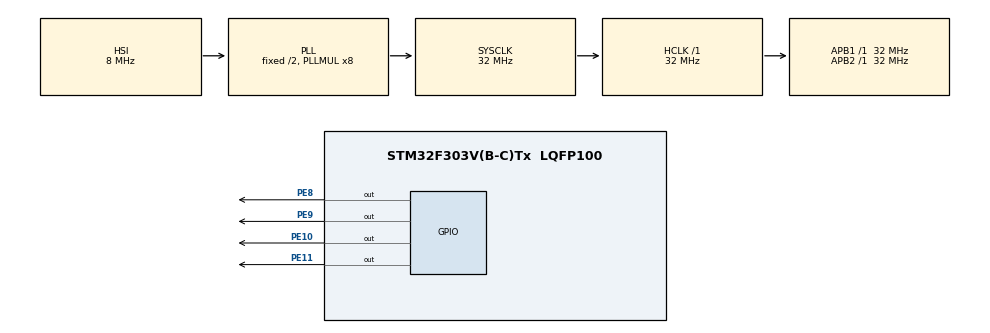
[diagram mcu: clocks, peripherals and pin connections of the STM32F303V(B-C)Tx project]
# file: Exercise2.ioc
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FREERTOS.Tasks01=defTask,24,128,StartDefaultTask,Default,NULL,Dynamic,NULL,NULL;BlinkLED,8,128,blink_LED,Default,NULL,Dynamic,NULL,NULL
FREERTOS.configUSE_IDLE_HOOK=1
Mcu.Family=STM32F3
Mcu.Name=STM32F303V(B-C)Tx
Mcu.Package=LQFP100
NVIC.PriorityGroup=NVIC_PRIORITYGROUP_4
NVIC.TIM1_UP_TIM16_IRQn=true\:0\:0\:false\:false\:true\:false\:false\:true
NVIC.TimeBase=TIM1_UP_TIM16_IRQn
NVIC.TimeBaseIP=TIM1
PE10.Signal=GPIO_Output
PE11.Signal=GPIO_Output
PE8.Signal=GPIO_Output
PE9.Signal=GPIO_Output
ProjectManager.HeapSize=0x200
ProjectManager.StackSize=0x400
ProjectManager.TargetToolchain=MDK-ARM V5.27
RCC.AHBFreq_Value=32000000
RCC.APB1Freq_Value=32000000
RCC.APB1TimFreq_Value=32000000
RCC.APB2Freq_Value=32000000
RCC.APB2TimFreq_Value=32000000
RCC.CortexFreq_Value=32000000
RCC.HCLKFreq_Value=32000000
RCC.HSE_VALUE=8000000
RCC.HSI_VALUE=8000000
RCC.LSE_VALUE=32768
RCC.PLLMUL=RCC_PLL_MUL8
RCC.SYSCLKFreq_VALUE=32000000
RCC.SYSCLKSourceVirtual=RCC_SYSCLKSOURCE_PLLCLK
RCC.USBFreq_Value=32000000
VP_FREERTOS_VS_CMSIS_V2.Mode=CMSIS_V2
VP_SYS_VS_tim1.Mode=TIM1
board=custom

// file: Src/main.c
/* USER CODE BEGIN Header */
/**
******************************************************************************
* @file           : main.c
* @brief          : Main program body
******************************************************************************
* @attention
*
* <h2><center>&copy; Copyright (c) 2020 STMicroelectronics.
* All rights reserved.</center></h2>
*
* This software component is licensed by ST under Ultimate Liberty license
* SLA0044, the "License"; You may not use this file except in compliance with
* the License. You may obtain a copy of the License at:
*                             www.st.com/SLA0044
*
******************************************************************************
*/
/* USER CODE END Header */

#include "main.h"
#include "cmsis_os.h"

#define CYCLE 6

/* Definitions for defTask */
osThreadId_t defTaskHandle;
const osThreadAttr_t defTask_attributes = {
	.name = "defTask",
	.priority = (osPriority_t) osPriorityNormal,
	.stack_size = 128
};
/* Definitions for BlinkLED */
osThreadId_t BlinkLEDHandle;
const osThreadAttr_t BlinkLED_attributes = {
	.name = "BlinkLED",
	.priority = (osPriority_t) osPriorityLow,
	.stack_size = 128
};

void SystemClock_Config(void);
static void MX_GPIO_Init(void);
void StartDefaultTask(void *argument);
void blink_LED(void *argument);

/* USER CODE BEGIN PFP */
osThreadId_t redBlinkTaskH;
osThreadId_t greenBlinkTaskH;
/* USER CODE END PFP */

int main(void)
{

	/* MCU Configuration--------------------------------------------------------*/

	/* Reset of all peripherals, Initializes the Flash interface and the Systick. */
	HAL_Init();

	/* Configure the system clock */
	SystemClock_Config();

	/* Initialize all configured peripherals */
	MX_GPIO_Init();
	/* Init scheduler */
	osKernelInitialize();

	/* Create the thread(s) */
	/* creation of defTask */
	defTaskHandle = osThreadNew(StartDefaultTask, NULL, &defTask_attributes);

	/* creation of BlinkLED */
	BlinkLEDHandle = osThreadNew(blink_LED, NULL, &BlinkLED_attributes);

	/* USER CODE BEGIN RTOS_THREADS */
	/* add threads, ... */

        /*
        * @brief Thread attribute to toggle red LED on GPIO9 on STM32 disccovery
        */
	const osThreadAttr_t redLed_attr = {
		.name = "Red",
		.priority = (osPriority_t) osPriorityLow,
		.stack_size = 128
	};
	redBlinkTaskH = osThreadNew(blink_LED, (uint16_t*)GPIO_PIN_9, &redLed_attr);

        /*
        * @brief Thread attribute to toggle green LED on GPIO11 on STM32
        */
	const osThreadAttr_t greenLed_attr = {
		.name = "Green",
		.priority = (osPriority_t) osPriorityLow,
		.stack_size = 128
	};
	greenBlinkTaskH = osThreadNew(blink_LED, (uint16_t*)GPIO_PIN_11, &greenLed_attr);

	/* USER CODE END RTOS_THREADS */

	/* Start scheduler */
	osKernelStart();

	/* We should never get here as control is now taken by the scheduler */

	/* Infinite loop */
	while (1)
	{

	}
}

void SystemClock_Config(void)
{
	RCC_OscInitTypeDef RCC_OscInitStruct = {0};
	RCC_ClkInitTypeDef RCC_ClkInitStruct = {0};

	/** Initializes the CPU, AHB and APB busses clocks
	 */
	RCC_OscInitStruct.OscillatorType = RCC_OSCILLATORTYPE_HSI;
	RCC_OscInitStruct.HSIState = RCC_HSI_ON;
	RCC_OscInitStruct.HSICalibrationValue = RCC_HSICALIBRATION_DEFAULT;
	RCC_OscInitStruct.PLL.PLLState = RCC_PLL_ON;
	RCC_OscInitStruct.PLL.PLLSource = RCC_PLLSOURCE_HSI;
	RCC_OscInitStruct.PLL.PLLMUL = RCC_PLL_MUL8;
	if (HAL_RCC_OscConfig(&RCC_OscInitStruct) != HAL_OK)
	{
		Error_Handler();
	}
	/** Initializes the CPU, AHB and APB busses clocks
	 */
	RCC_ClkInitStruct.ClockType = RCC_CLOCKTYPE_HCLK|RCC_CLOCKTYPE_SYSCLK
		|RCC_CLOCKTYPE_PCLK1|RCC_CLOCKTYPE_PCLK2;
	RCC_ClkInitStruct.SYSCLKSource = RCC_SYSCLKSOURCE_PLLCLK;
	RCC_ClkInitStruct.AHBCLKDivider = RCC_SYSCLK_DIV1;
	RCC_ClkInitStruct.APB1CLKDivider = RCC_HCLK_DIV1;
	RCC_ClkInitStruct.APB2CLKDivider = RCC_HCLK_DIV1;

	if (HAL_RCC_ClockConfig(&RCC_ClkInitStruct, FLASH_LATENCY_1) != HAL_OK)
	{
		Error_Handler();
	}
}

static void MX_GPIO_Init(void)
{
	GPIO_InitTypeDef GPIO_InitStruct = {0};

	/* GPIO Ports Clock Enable */
	__HAL_RCC_GPIOE_CLK_ENABLE();

	/*Configure GPIO pin Output Level */
	HAL_GPIO_WritePin(GPIOE, GPIO_PIN_8|GPIO_PIN_9|GPIO_PIN_10|GPIO_PIN_11, GPIO_PIN_RESET);

	/*Configure GPIO pins : PE8 PE9 PE10 PE11 */
	GPIO_InitStruct.Pin = GPIO_PIN_8|GPIO_PIN_9|GPIO_PIN_10|GPIO_PIN_11;
	GPIO_InitStruct.Mode = GPIO_MODE_OUTPUT_PP;
	GPIO_InitStruct.Pull = GPIO_NOPULL;
	GPIO_InitStruct.Speed = GPIO_SPEED_FREQ_LOW;
	HAL_GPIO_Init(GPIOE, &GPIO_InitStruct);

}

void StartDefaultTask(void *argument)
{
	for(;;)
	{
		osDelay(1);
	}
}

void blink_LED(void *argument)
{
 /* USER CODE BEGIN ledController */
	uint8_t count = 0;

  /* Infinite loop */
  for(;;)
  {
          ++count;
          HAL_GPIO_TogglePin(GPIOE, (uint16_t)argument);
          switch(count) {
                  case CYCLE:
                          osThreadTerminate(redBlinkTaskH);
                          osThreadTerminate(greenBlinkTaskH);
                  break;
                  case 2*CYCLE:
                          osThreadSetPriority(BlinkLEDHandle, (osPriority_t)osPriorityNormal);
                  break;
                  case 4*CYCLE:
                        osThreadTerminate(blink_LED);
                  break;
                }
          osDelay(500);
   }
}

void HAL_TIM_PeriodElapsedCallback(TIM_HandleTypeDef *htim)
{
	if (htim->Instance == TIM1) {
		HAL_IncTick();
	}
}

void Error_Handler(void)
{
}

/************************ (C) COPYRIGHT STMicroelectronics *****END OF FILE****/
